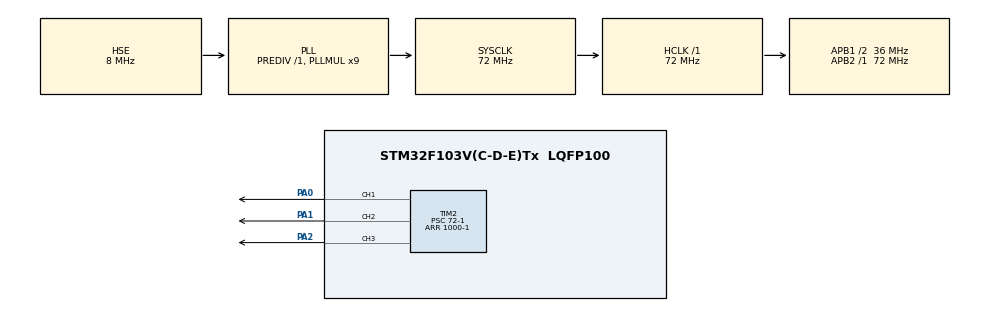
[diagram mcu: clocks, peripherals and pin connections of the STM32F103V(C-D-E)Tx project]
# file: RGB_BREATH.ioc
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Mcu.Family=STM32F1
Mcu.Name=STM32F103V(C-D-E)Tx
Mcu.Package=LQFP100
NVIC.PriorityGroup=NVIC_PRIORITYGROUP_4
OSC_IN.Mode=HSE-External-Oscillator
OSC_IN.Signal=RCC_OSC_IN
OSC_OUT.Mode=HSE-External-Oscillator
OSC_OUT.Signal=RCC_OSC_OUT
PA0-WKUP.Signal=S_TIM2_CH1_ETR
PA1.Signal=S_TIM2_CH2
PA13.Mode=Serial_Wire
PA13.Signal=SYS_JTMS-SWDIO
PA14.Mode=Serial_Wire
PA14.Signal=SYS_JTCK-SWCLK
PA2.Signal=S_TIM2_CH3
PC14-OSC32_IN.Mode=LSE-External-Oscillator
PC14-OSC32_IN.Signal=RCC_OSC32_IN
PC15-OSC32_OUT.Mode=LSE-External-Oscillator
PC15-OSC32_OUT.Signal=RCC_OSC32_OUT
ProjectManager.HeapSize=0x200
ProjectManager.StackSize=0x400
ProjectManager.TargetToolchain=MDK-ARM V5
RCC.AHBFreq_Value=72000000
RCC.APB1CLKDivider=RCC_HCLK_DIV2
RCC.APB1Freq_Value=36000000
RCC.APB1TimFreq_Value=72000000
RCC.APB2Freq_Value=72000000
RCC.APB2TimFreq_Value=72000000
RCC.HCLKFreq_Value=72000000
RCC.PLLMUL=RCC_PLL_MUL9
RCC.PLLSourceVirtual=RCC_PLLSOURCE_HSE
RCC.SYSCLKFreq_VALUE=72000000
RCC.SYSCLKSource=RCC_SYSCLKSOURCE_PLLCLK
RCC.USBFreq_Value=72000000
SH.S_TIM2_CH1_ETR.0=TIM2_CH1,PWM Generation1 CH1
SH.S_TIM2_CH2.0=TIM2_CH2,PWM Generation2 CH2
SH.S_TIM2_CH3.0=TIM2_CH3,PWM Generation3 CH3
TIM2.Channel-PWM\ Generation1\ CH1=TIM_CHANNEL_1
TIM2.Channel-PWM\ Generation2\ CH2=TIM_CHANNEL_2
TIM2.Channel-PWM\ Generation3\ CH3=TIM_CHANNEL_3
TIM2.Period=1000-1
TIM2.Prescaler=72-1
TIM2.Pulse-PWM\ Generation1\ CH1=500-1
TIM2.Pulse-PWM\ Generation2\ CH2=500-1
TIM2.Pulse-PWM\ Generation3\ CH3=500-1
VP_TIM2_VS_ClockSourceINT.Mode=Internal
board=custom

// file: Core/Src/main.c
/* USER CODE BEGIN Header */
/**
  ******************************************************************************
  * @file           : main.c
  * @brief          : Main program body
  ******************************************************************************
  * @attention
  *
  * Copyright (c) 2024 STMicroelectronics.
  * All rights reserved.
  *
  * This software is licensed under terms that can be found in the LICENSE file
  * in the root directory of this software component.
  * If no LICENSE file comes with this software, it is provided AS-IS.
  *
  ******************************************************************************
  */
/* USER CODE END Header */
#include "main.h"
#include "tim.h"
#include "gpio.h"

/* USER CODE BEGIN PV */
uint32_t LED_Delay = 0;
float hue = 0.0f;         // HSV色相�? (0-360�?)
float brightness = 0.0f;   // 亮度�? (0-1)
uint16_t rgb_value[3] = {999, 999, 999};  // RGB三个通道的PWM�? (0-999)
#define PI 3.14159f
/* USER CODE END PV */

void SystemClock_Config(void);
/* USER CODE BEGIN PFP */
void HSV_to_RGB(float h, float s, float v);
void RGB_Breath(void);
/* USER CODE END PFP */

/* USER CODE BEGIN 0 */
// HSV转RGB函数
void HSV_to_RGB(float h, float s, float v) {
    float r, g, b;
    float c = v * s;
    float x = c * (1 - fabsf(fmodf(h / 60.0f, 2) - 1));
    float m = v - c;

    if(h >= 0 && h < 60) {
        r = c; g = x; b = 0;
    } else if(h >= 60 && h < 120) {
        r = x; g = c; b = 0;
    } else if(h >= 120 && h < 180) {
        r = 0; g = c; b = x;
    } else if(h >= 180 && h < 240) {
        r = 0; g = x; b = c;
    } else if(h >= 240 && h < 300) {
        r = x; g = 0; b = c;
    } else {
        r = c; g = 0; b = x;
    }

    // 将RGB值映射到PWM范围�?0-999），并反转（因为0是最亮）
    rgb_value[0] = 999 - (uint16_t)((r + m) * 999);
    rgb_value[1] = 999 - (uint16_t)((g + m) * 999);
    rgb_value[2] = 999 - (uint16_t)((b + m) * 999);
}

void RGB_Breath(void)
{
    static uint32_t time_count = 0;

    // 使用正弦函数产生平滑的亮度变�?
    brightness = (sinf(time_count * PI / 180.0f) + 1.0f) * 0.5f;  // 产生0-1的正弦波
    brightness = brightness * 0.8f + 0.1f;  // 将亮度范围限制在10%-90%

    // 缓慢改变色相
    hue += 0.5f;
    if(hue >= 360.0f) {
        hue = 0.0f;
    }

    // 转换HSV到RGB
    HSV_to_RGB(hue, 1.0f, brightness);

    // 更新PWM�?
    __HAL_TIM_SET_COMPARE(&htim2, TIM_CHANNEL_1, rgb_value[0]);
    __HAL_TIM_SET_COMPARE(&htim2, TIM_CHANNEL_2, rgb_value[1]);
    __HAL_TIM_SET_COMPARE(&htim2, TIM_CHANNEL_3, rgb_value[2]);

    // 控制变化速度
    time_count++;
    if(time_count >= 360) {
        time_count = 0;
    }

    HAL_Delay(10);  // 降低更新速度，使呼吸更加柔和
}
/* USER CODE END 0 */

int main(void)
{

  /* MCU Configuration--------------------------------------------------------*/

  /* Reset of all peripherals, Initializes the Flash interface and the Systick. */
  HAL_Init();

  /* Configure the system clock */
  SystemClock_Config();

  /* Initialize all configured peripherals */
  MX_GPIO_Init();
  MX_TIM2_Init();
  /* USER CODE BEGIN 2 */

  // 启动PWM输出
  HAL_TIM_PWM_Start(&htim2, TIM_CHANNEL_1);
  HAL_TIM_PWM_Start(&htim2, TIM_CHANNEL_2);
  HAL_TIM_PWM_Start(&htim2, TIM_CHANNEL_3);

  // 初始化RGB值（全暗�?
  rgb_value[0] = 999;
  rgb_value[1] = 999;
  rgb_value[2] = 999;
  /* USER CODE END 2 */

  /* Infinite loop */
  while (1)
  {

    /* USER CODE BEGIN 3 */
    RGB_Breath();
  }
  /* USER CODE END 3 */
}

void SystemClock_Config(void)
{
  RCC_OscInitTypeDef RCC_OscInitStruct = {0};
  RCC_ClkInitTypeDef RCC_ClkInitStruct = {0};

  /** Initializes the RCC Oscillators according to the specified parameters
  * in the RCC_OscInitTypeDef structure.
  */
  RCC_OscInitStruct.OscillatorType = RCC_OSCILLATORTYPE_HSE;
  RCC_OscInitStruct.HSEState = RCC_HSE_ON;
  RCC_OscInitStruct.HSEPredivValue = RCC_HSE_PREDIV_DIV1;
  RCC_OscInitStruct.HSIState = RCC_HSI_ON;
  RCC_OscInitStruct.PLL.PLLState = RCC_PLL_ON;
  RCC_OscInitStruct.PLL.PLLSource = RCC_PLLSOURCE_HSE;
  RCC_OscInitStruct.PLL.PLLMUL = RCC_PLL_MUL9;
  if (HAL_RCC_OscConfig(&RCC_OscInitStruct) != HAL_OK)
  {
    Error_Handler();
  }

  /** Initializes the CPU, AHB and APB buses clocks
  */
  RCC_ClkInitStruct.ClockType = RCC_CLOCKTYPE_HCLK|RCC_CLOCKTYPE_SYSCLK
                              |RCC_CLOCKTYPE_PCLK1|RCC_CLOCKTYPE_PCLK2;
  RCC_ClkInitStruct.SYSCLKSource = RCC_SYSCLKSOURCE_PLLCLK;
  RCC_ClkInitStruct.AHBCLKDivider = RCC_SYSCLK_DIV1;
  RCC_ClkInitStruct.APB1CLKDivider = RCC_HCLK_DIV2;
  RCC_ClkInitStruct.APB2CLKDivider = RCC_HCLK_DIV1;

  if (HAL_RCC_ClockConfig(&RCC_ClkInitStruct, FLASH_LATENCY_2) != HAL_OK)
  {
    Error_Handler();
  }
}

void Error_Handler(void)
{
  __disable_irq();
  while (1)
  {
  }
}
